AUTOSAR XML (schema 00046)
package /Runnables
  sender receiver interface SRIF_Throttle
    data CMD: type=uint32
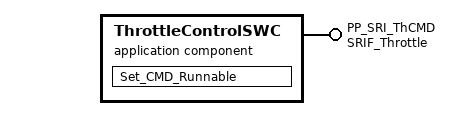
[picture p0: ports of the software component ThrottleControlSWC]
  application sw component type ThrottleControlSWC
    provide port PP_SRI_ThCMD: provided-interface=SRIF_Throttle
    behavior ThrottleControl_Behavior
      runnable Set_CMD_Runnable: symbol=SET_CMD
        data-write-access:
          access CMD_DATA: accessed-variable=PP_SRI_ThCMD.CMD
